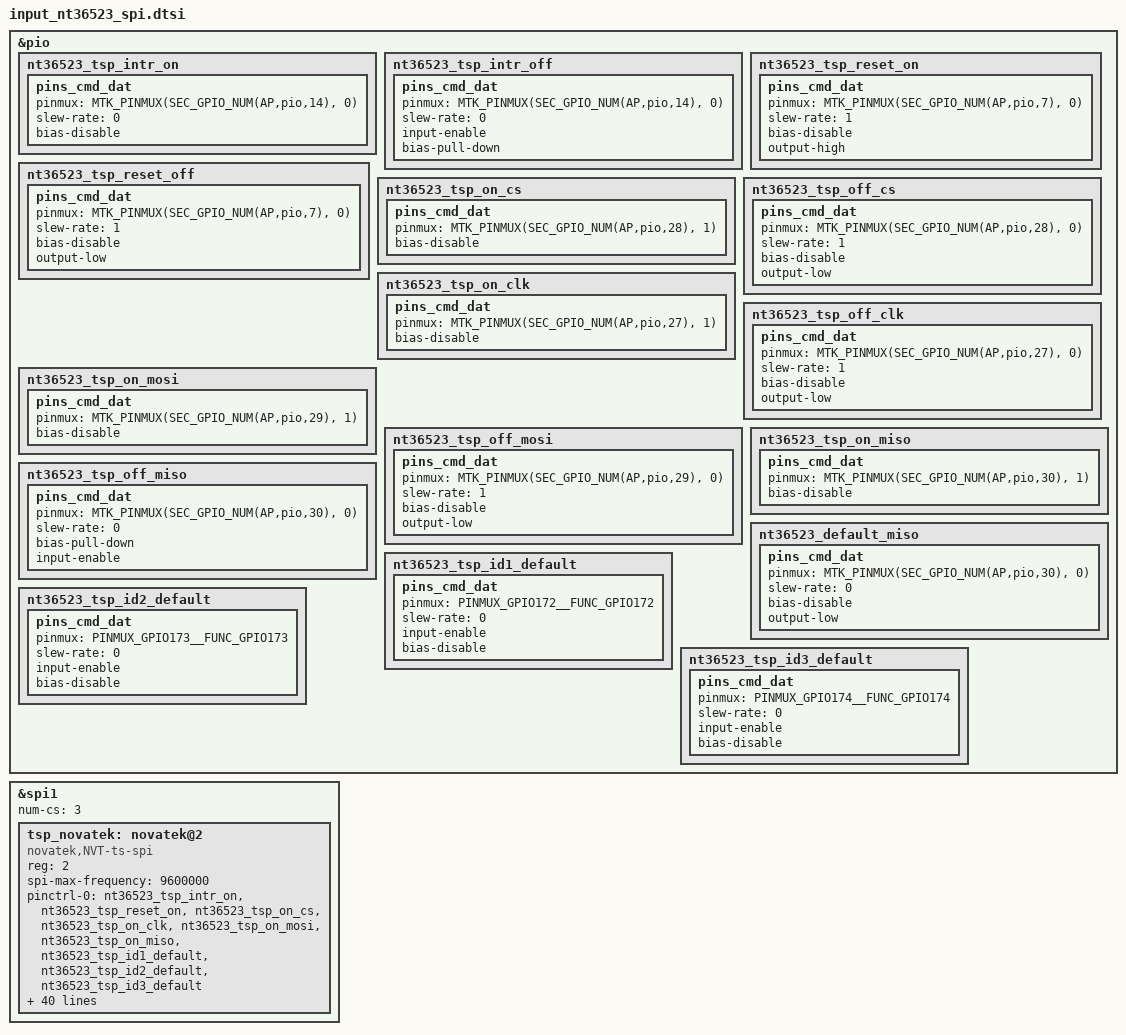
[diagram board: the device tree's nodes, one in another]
/* NEED TO FIX IF YOU WANT USE THIS */

&pio {
	nt36523_tsp_intr_on: nt36523_tsp_intr_on {
		pins_cmd_dat {
			pinmux = <MTK_PINMUX(SEC_GPIO_NUM(AP,pio,14), 0)>;
			slew-rate = <0>;
			bias-disable;
		};
	};

	nt36523_tsp_intr_off: nt36523_tsp_intr_off {
		pins_cmd_dat {
			pinmux = <MTK_PINMUX(SEC_GPIO_NUM(AP,pio,14), 0)>;
			slew-rate = <0>;
			input-enable;
			bias-pull-down;
		};
	};
};
&pio {
	nt36523_tsp_reset_on: nt36523_tsp_reset_on {
		pins_cmd_dat{
			pinmux = <MTK_PINMUX(SEC_GPIO_NUM(AP,pio,7), 0)>;
			slew-rate = <1>;
			bias-disable;
			output-high;
		};
	};

	nt36523_tsp_reset_off: nt36523_tsp_reset_off {
		pins_cmd_dat{
			pinmux = <MTK_PINMUX(SEC_GPIO_NUM(AP,pio,7), 0)>;
			slew-rate = <1>;
			bias-disable;
			output-low;
		};
	};
};
&pio {
	nt36523_tsp_on_cs: nt36523_tsp_on_cs {
		pins_cmd_dat{
			pinmux = <MTK_PINMUX(SEC_GPIO_NUM(AP,pio,28), 1)>;
			bias-disable;
		};
	};
	nt36523_tsp_off_cs: nt36523_tsp_off_cs {
		pins_cmd_dat{
			pinmux = <MTK_PINMUX(SEC_GPIO_NUM(AP,pio,28), 0)>;
			slew-rate = <1>;
			bias-disable;
			output-low;
		};
	};
};
&pio {
	nt36523_tsp_on_clk: nt36523_tsp_on_clk {
		pins_cmd_dat{
			pinmux = <MTK_PINMUX(SEC_GPIO_NUM(AP,pio,27), 1)>;
			bias-disable;
		};
	};
	nt36523_tsp_off_clk: nt36523_tsp_off_clk {
		pins_cmd_dat{
			pinmux = <MTK_PINMUX(SEC_GPIO_NUM(AP,pio,27), 0)>;
			slew-rate = <1>;
			bias-disable;
			output-low;
		};
	};

	nt36523_tsp_on_mosi: nt36523_tsp_on_mosi {
		pins_cmd_dat{
			pinmux = <MTK_PINMUX(SEC_GPIO_NUM(AP,pio,29), 1)>;
			bias-disable;
		};
	};
	nt36523_tsp_off_mosi: nt36523_tsp_off_mosi {
		pins_cmd_dat{
			pinmux = <MTK_PINMUX(SEC_GPIO_NUM(AP,pio,29), 0)>;
			slew-rate = <1>;
			bias-disable;
			output-low;
		};
	};

	nt36523_tsp_on_miso: nt36523_tsp_on_miso {
		pins_cmd_dat{
			pinmux = <MTK_PINMUX(SEC_GPIO_NUM(AP,pio,30), 1)>;
			bias-disable;
		};
	};

	nt36523_tsp_off_miso: nt36523_tsp_off_miso {
		pins_cmd_dat{
			pinmux = <MTK_PINMUX(SEC_GPIO_NUM(AP,pio,30), 0)>;
			slew-rate = <0>;
			bias-pull-down;
			input-enable;
		};
	};

	nt36523_default_miso: nt36523_default_miso {
		pins_cmd_dat{
			pinmux = <MTK_PINMUX(SEC_GPIO_NUM(AP,pio,30), 0)>;
			slew-rate = <0>;
			bias-disable;
			output-low;
		};
	};
};

&spi1 {
	status = "okay";
	#address-cells = <1>;
	#size-cells = <0>;
	num-cs = <1>;
	tsp_novatek: novatek@2 {
		status = "okay";
		compatible = "novatek,NVT-ts-spi";
		reg = <2>; //Same as CS ID
		spi-max-frequency = <9600000>;

		pinctrl-names = "default", "on_state", "off_state";
		pinctrl-0 = <&nt36523_tsp_intr_on &nt36523_tsp_reset_on &nt36523_tsp_on_cs &nt36523_tsp_on_clk &nt36523_tsp_on_mosi &nt36523_tsp_on_miso>;
		pinctrl-1 = <&nt36523_tsp_intr_on &nt36523_tsp_reset_on &nt36523_tsp_on_cs &nt36523_tsp_on_clk &nt36523_tsp_on_mosi &nt36523_tsp_on_miso>;
		pinctrl-2 = <&nt36523_tsp_intr_off &nt36523_tsp_reset_off &nt36523_tsp_off_cs &nt36523_tsp_off_clk &nt36523_tsp_off_mosi &nt36523_tsp_off_miso>;

		novatek,reset-gpio = <SEC_GPIO_REF(AP,pio,7) 0x00>;
		novatek,irq-gpio = <SEC_GPIO_REF(AP,pio,14) 0x2002>;

		novatek,enable_sysinput_enabled;
	};
};
/* /home/dpi/qb5_8814/workspace/P4_1716/android/kernel/kmodule/input/touchscreen/novatek/nt36523_spi/dts/input-mtk-tsp-nt36523-spi.a13x.dtsi */
&pio {
	nt36523_tsp_id1_default: nt36523_tsp_id1_default {
		pins_cmd_dat {
			pinmux = <PINMUX_GPIO172__FUNC_GPIO172>;
			slew-rate = <0>;
			input-enable;
			bias-disable;
		};
	};

	nt36523_tsp_id2_default: nt36523_tsp_id2_default {
		pins_cmd_dat {
			pinmux = <PINMUX_GPIO173__FUNC_GPIO173>;
			slew-rate = <0>;
			input-enable;
			bias-disable;
		};
	};

	nt36523_tsp_id3_default: nt36523_tsp_id3_default {
		pins_cmd_dat {
			pinmux = <PINMUX_GPIO174__FUNC_GPIO174>;
			slew-rate = <0>;
			input-enable;
			bias-disable;
		};
	};
};

&spi1 {
	num-cs = <3>;
};

&tsp_novatek{
	pinctrl-names = "default", "on_state", "off_state";
	pinctrl-0 = <&nt36523_tsp_intr_on &nt36523_tsp_reset_on &nt36523_tsp_on_cs &nt36523_tsp_on_clk &nt36523_tsp_on_mosi &nt36523_tsp_on_miso &nt36523_tsp_id1_default &nt36523_tsp_id2_default &nt36523_tsp_id3_default>;
	pinctrl-1 = <&nt36523_tsp_intr_on &nt36523_tsp_reset_on &nt36523_tsp_on_cs &nt36523_tsp_on_clk &nt36523_tsp_on_mosi &nt36523_tsp_on_miso &nt36523_tsp_id1_default &nt36523_tsp_id2_default &nt36523_tsp_id3_default>;
	pinctrl-2 = <&nt36523_tsp_intr_off &nt36523_tsp_reset_off &nt36523_tsp_off_cs &nt36523_tsp_off_clk &nt36523_tsp_off_mosi &nt36523_tsp_off_miso &nt36523_tsp_id1_default &nt36523_tsp_id2_default &nt36523_tsp_id3_default>;

	novatek,resolution = <720 1600>;
	novatek,enable_settings_aot;
	novatek,support_ear_detect_mode;
	novatek,prox_lp_scan_enabled;

	novatek,lcdid1-gpio = <&pio 172 0x0>;
	novatek,lcdid2-gpio = <&pio 173 0x0>;
	novatek,lcdid3-gpio = <&pio 174 0x0>;
	novatek,lcdid = <3 6>;	// 0,0,0,BOE,0,0,sharp
	novatek,lcdtype = <0 0 0 0x2a6244 0 0 0x2af244>;
	novatek,fw_name = "","","","tsp_novatek/nt36525c_a13x_boe.bin","","","tsp_novatek/nt36525c_a13x_sharp.bin";
	novatek,fw_name_mp = "","","","tsp_novatek/nt36525c_a13x_mp_boe.bin","","","tsp_novatek/nt36525c_a13x_mp_sharp.bin";

	novatek,name_lcd_vddi = "vcamio";
	novatek,name_lcd_rst = "gpio_lcd_rst";
	novatek,name_lcd_bl_en = "gpio_lcd_bl_en";

	/* 672A, 525B, 675, 526, 672C */
	novatek,swrst-n8-addr = <0x03F0FE>;
	novatek,spi-rd-fast-addr = <0x03F310>;
	/* MP */
	novatek,mp-support-dt;
	/* nt36525_a12_ltps */
//	novatek-mp-criteria-722A@3 {
//		#address-cells = <1>;
//		#size-cells = <0>;
//		compatible = "novatek-mp-criteria-722A";
		/* sec cmd test config */
//		open_test_spec = <(-511) 5120>;
//		short_test_spec = <10000 14008>;
//		diff_test_frame = <50>;
		/* sec cmd fdm test config */
//		fdm_x_num = <2>;
//		fdm_diff_test_frame = <50>;
//	};
};
